# apb_pulpino: IP-XACT component
VLNV pulp-platform.org:peripheral:apb_pulpino:1.0

## Parameters
REG_PAD_MUX = 4'b0000
REG_CLK_GATE = 4'b0001
REG_BOOT_ADR = 4'b0010
REG_INFO = 4'b0100
REG_STATUS = 4'b0101
REG_PADCFG0 = 4'b1000 — BASEADDR+0x20
REG_PADCFG1 = 4'b1001 — BASEADDR+0x24
REG_PADCFG2 = 4'b1010 — BASEADDR+0x28
REG_PADCFG3 = 4'b1011 — BASEADDR+0x2C
REG_PADCFG4 = 4'b1100 — BASEADDR+0x30
REG_PADCFG5 = 4'b1101 — BASEADDR+0x34
REG_PADCFG6 = 4'b1110 — BASEADDR+0x38
REG_PADCFG7 = 4'b1111 — BASEADDR+0x3C
VERSION = 5'b00010 — Version number 1.0
DATA_RAM = 8'b00000100 — size of data ram in multiples of 8 kBye
INSTR_RAM = 8'b00000100 — size of instr ram in multiples of 8 kBye
ROM = 5'b00000 — size of ROM in kByte - floor to nearest
ICACHE = 1'b0 — has instruction cache
DCACHE = 1'b0 — has data cache
APB_ADDR_WIDTH = 12 — APB slaves are 4KB by default
BOOT_ADDR = 32'h8000

## Bus interfaces (logical=physical port)
apb_slave: slave amba.com:AMBA3:APB:r1p0_4, memory map SOC_CONTROL
  PADDR[11:0]=PADDR, PSELx[0:0]=PSEL[0:0], PENABLE[0:0]=PENABLE[0:0], PWRITE[0:0]=PWRITE[0:0], PRDATA=PRDATA, PWDATA=PWDATA, PREADY[0:0]=PREADY[0:0], PSLVERR[0:0]=PSLVERR[0:0]

## Ports
in PADDR[APB_ADDR_WIDTH-1:0]
in PSEL
in PENABLE
in PWRITE
out PRDATA[31:0]
in PWDATA[31:0]
out PREADY
out PSLVERR
in HCLK
in HRESETn
out pad_cfg_o[5:0]
out clk_gate_o[31:0]
out pad_mux_o[31:0]
out boot_addr_o[31:0]

## Address spaces and blocks
SOC_CONTROL.soc_control_registers: base 'h0, range 'h40, width 32

## Registers
Registers are 32-bit, access not given, no defined reset value unless marked. A register's access mark holds for its fields unless they carry their own. Offsets are from the block's base; lines under a group give offsets from that group; [hi:lo] are bit positions; {n}, {i} and the like mark numbered series; 'fields as' and 'values as' point back to an identical list; <NAME> marks a mode.

## SOC_CONTROL.soc_control_registers
Base 0x00000000
0x00 PAD_MUX
  [31:0] PADMUX
0x04 CLK_GATE
  [0] E
0x08 BOOT_ADR
  [31:0] BOOT_ADDRESS
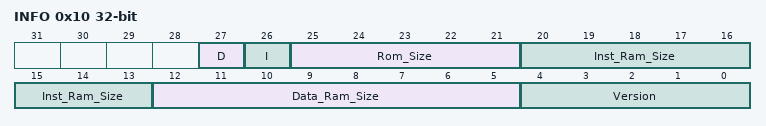
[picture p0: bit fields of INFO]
0x10 INFO
  [27] D, [26] I, [25:21] Rom_Size, [20:13] Inst_Ram_Size, [12:5] Data_Ram_Size, [4:0] Version
0x14 STATUS
  [0] S
{0x20+4i} PAD_CFG[{i}] (i=0..7)
  [31:0] PAD_Configuration
